# STM32H7P5xx register map
File version: 1.0
Registers are 32-bit, read-write, reset 0x0 unless marked. A register's access mark holds for its fields unless they carry their own. Offsets are from the block's base; [hi:lo] are bit positions; {n}, {i} and the like mark numbered series.

## EXTI — Extended interrupt and event controller (EXTI)
Base 0x58000000
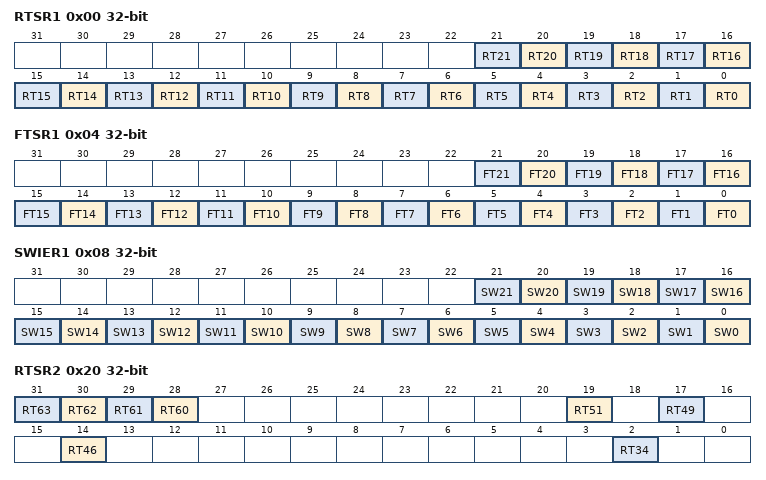
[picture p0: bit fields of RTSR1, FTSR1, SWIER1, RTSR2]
0x00 RTSR1 — EXTI rising trigger selection register 1
  [n] RT{n} (n=0..21)
0x04 FTSR1 — EXTI falling trigger selection register 1
  [n] FT{n} (n=0..21)
0x08 SWIER1 — EXTI software interrupt event register 1
  [n] SW{n} (n=0..21) — Software interrupt on event i
0x20 RTSR2 — EXTI rising trigger selection register 2
  [n-32] RT{n} (n=60..63), [19] RT51, [17] RT49, [14] RT46, [2] RT34
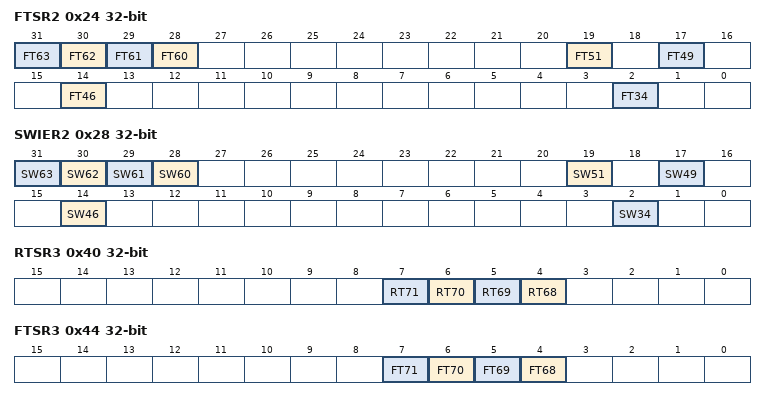
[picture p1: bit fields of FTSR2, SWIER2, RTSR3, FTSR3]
0x24 FTSR2 — EXTI falling trigger selection register 2
  [n-32] FT{n} (n=60..63), [19] FT51, [17] FT49, [14] FT46, [2] FT34
0x28 SWIER2 — EXTI software interrupt event register 2
  [n-32] SW{n} (n=60..63) — Software interrupt on event i
  [19] SW51 — Software interrupt on event 51
  [17] SW49 — Software interrupt on event 49
  [14] SW46 — Software interrupt on event 46
  [2] SW34 — Software interrupt on event 34
0x40 RTSR3 — EXTI rising trigger selection register 3
  [n-64] RT{n} (n=68..71)
0x44 FTSR3 — EXTI falling trigger selection register 3
  [n-64] FT{n} (n=68..71)
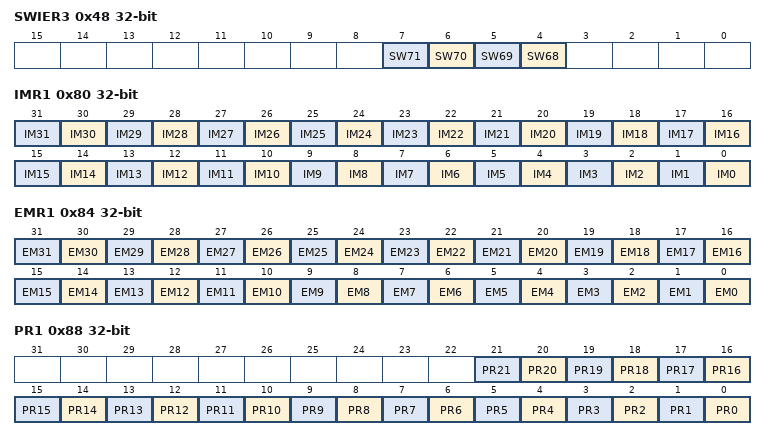
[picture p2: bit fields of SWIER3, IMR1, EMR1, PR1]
0x48 SWIER3 — EXTI software interrupt event register 3
  [n-64] SW{n} (n=68..71) — Software interrupt on event i
0x80 IMR1 — EXTI interrupt mask register 1
  [n] IM{n} (n=0..31) — CPU interrupt mask on event input i
0x84 EMR1 — EXTI event mask register 1
  [n] EM{n} (n=0..31) — CPU event mask on event input i
0x88 PR1 — EXTI pending register 1
  [n] PR{n} (n=0..21) — Configurable event input i pending
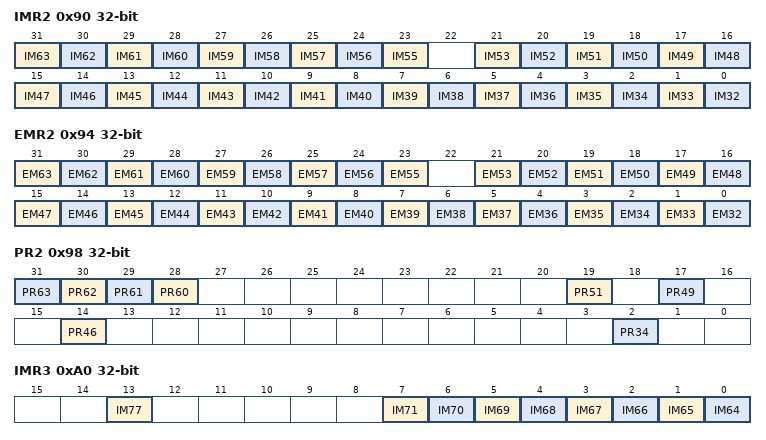
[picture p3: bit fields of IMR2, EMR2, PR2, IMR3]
0x90 IMR2 — EXTI interrupt mask register 2
  [n-32] IM{n} (n=55..63) — CPU interrupt mask on event input i
  [n-32] IM{n} (n=32..53)
0x94 EMR2 — EXTI event mask register 2
  [n-32] EM{n} (n=55..63) — CPU event mask on event input i
  [n-32] EM{n} (n=32..53) — CPU event mask on event input i
0x98 PR2 — EXTI pending register 2
  [n-32] PR{n} (n=60..63) — Configurable event input i pending
  [19] PR51 — Configurable event input 51 pending bit
  [17] PR49 — Configurable event input 49 pending bit
  [14] PR46 — Configurable event input 46 pending bit
  [2] PR34 — Configurable event input 34 pending bit
0xA0 IMR3 — EXTI interrupt mask register 3
  [13] IM77 — CPU interrupt mask on direct event input 77
  [n-64] IM{n} (n=64..71)
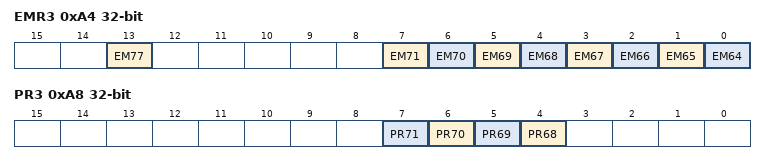
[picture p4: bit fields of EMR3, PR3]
0xA4 EMR3 — EXTI event mask register 3
  [13] EM77 — CPU event mask on event input 77
  [n-64] EM{n} (n=64..71) — CPU event mask on event input i
0xA8 PR3 — EXTI pending register 3
  [n-64] PR{n} (n=68..71) — Configurable event input i pending bit

## SBS — System configuration, Boot and Security (SBS)
Base 0x58000400
0x00 BOOTSR ro — SBS boot status register
  [31:0] INITVTOR — Initial vector for Cortex-M7
0x10 HDPLCR — SBS hide protection control register
  [7:0] INCR_HDPL — Increment HDPL
0x14 HDPLSR ro — SBS hide protection status register
  [7:0] HDPL — Hide protection level
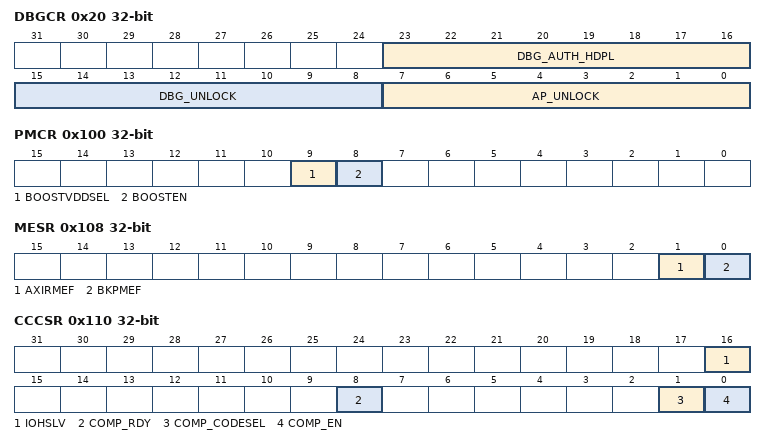
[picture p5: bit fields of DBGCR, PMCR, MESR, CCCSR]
0x20 DBGCR — SBS debug control register
  [23:16] DBG_AUTH_HDPL
  [15:8] DBG_UNLOCK — Debug unlock
  [7:0] AP_UNLOCK — Access port unlock
0x24 DBGLOCKR — SBS debug lock register
  [7:0] DBGCFG_LOCK — Debug configuration lock
0x34 RSSCMDR — SBS RSS command register
  [15:0] RSSCMD — RSS command
0x100 PMCR — SBS product mode and configuration register
  [9] BOOSTVDDSEL — Booster VDD selection
  [8] BOOSTEN — Booster enable
0x104 FPUIMR — SBS FPU interrupt mask register
  [5:0] FPU_IE — FPU interrupt enable
0x108 MESR ro — SBS memory erase status register
  [1] AXIRMEF — AXISRAM1 memory erase flag
  [0] BKPMEF — Backup SRAM memory erase flag
0x110 CCCSR — SBS I/O compensation cell control and status register
  [16] IOHSLV — I/O high speed at low voltage
  [8] COMP_RDY — Compensation cell ready
  [1] COMP_CODESEL — Compensation cell code selection
  [0] COMP_EN — Compensation cell enable
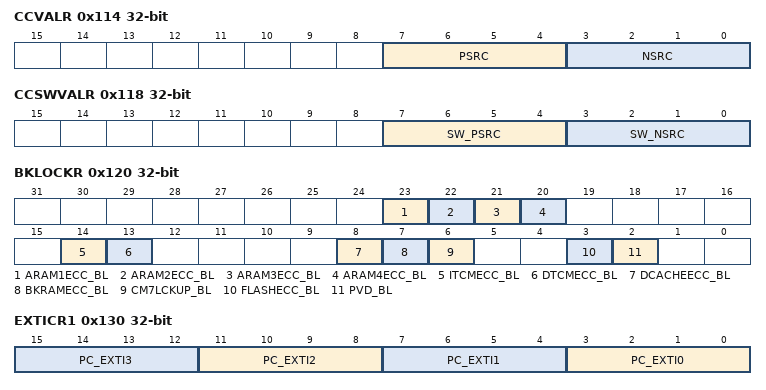
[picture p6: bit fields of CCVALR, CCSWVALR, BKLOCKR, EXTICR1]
0x114 CCVALR ro — SBS compensation cell for I/Os value register
  [7:4] PSRC, [3:0] NSRC
0x118 CCSWVALR — SBS compensation cell for I/Os software value register
  [7:4] SW_PSRC, [3:0] SW_NSRC
0x120 BKLOCKR — SBS break lock register
  [24-n] ARAM{n}ECC_BL (n=1..4) — AXISRAM{n} ECC error break lock
  [14] ITCMECC_BL — ITCM ECC error break lock
  [13] DTCMECC_BL — DTCM ECC error break lock
  [8] DCACHEECC_BL — D-Cache ECC error break lock
  [7] BKRAMECC_BL — Backup RAM ECC error break lock
  [6] CM7LCKUP_BL — Cortex-M7 lockup break lock
  [3] FLASHECC_BL — Flash ECC error break lock
  [2] PVD_BL — PVD break lock
0x130 EXTICR1 — SBS external interrupt configuration registers
  [4n+3:4n] PC_EXTI{n} (n=0..3) — Port configuration for EXTI{n}
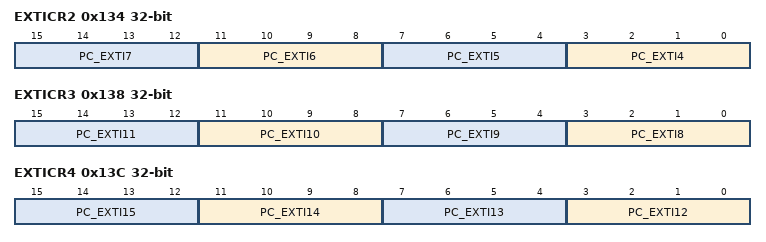
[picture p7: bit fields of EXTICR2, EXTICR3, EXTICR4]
0x134 EXTICR2 — SBS external interrupt configuration registers
  [4n-13:4n-16] PC_EXTI{n} (n=4..7) — Port configuration for EXTI{n}
0x138 EXTICR3 — SBS external interrupt configuration registers
  [4n-29:4n-32] PC_EXTI{n} (n=8..11) — Port configuration for EXTI{n}
0x13C EXTICR4 — SBS external interrupt configuration registers
  [4n-45:4n-48] PC_EXTI{n} (n=12..15) — Port configuration for EXTI{n}
